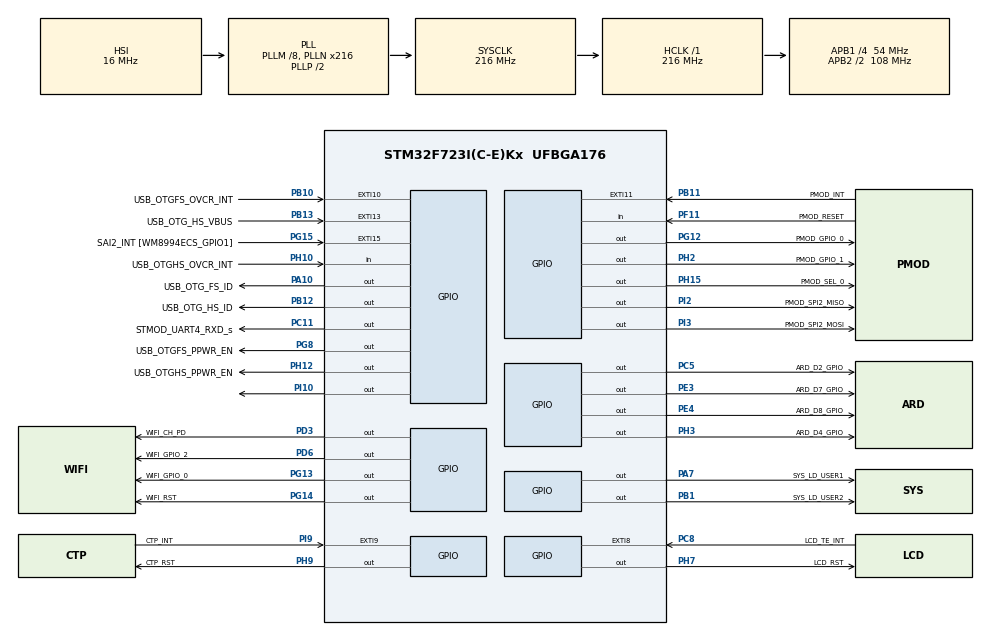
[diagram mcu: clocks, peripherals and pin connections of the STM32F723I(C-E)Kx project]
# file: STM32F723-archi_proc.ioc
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CORTEX_M7.AccessPermission-Cortex_Memory_Protection_Unit_Region0_Settings=MPU_REGION_FULL_ACCESS
CORTEX_M7.BaseAddress-Cortex_Memory_Protection_Unit_Region0_Settings=0x64000000
CORTEX_M7.CPU_DCache=Enabled
CORTEX_M7.CPU_ICache=Enabled
CORTEX_M7.Enable-Cortex_Memory_Protection_Unit_Region0_Settings=MPU_REGION_ENABLE
CORTEX_M7.IsBufferable-Cortex_Memory_Protection_Unit_Region0_Settings=MPU_ACCESS_BUFFERABLE
CORTEX_M7.IsCacheable-Cortex_Memory_Protection_Unit_Region0_Settings=MPU_ACCESS_CACHEABLE
CORTEX_M7.IsShareable-Cortex_Memory_Protection_Unit_Region0_Settings=MPU_ACCESS_SHAREABLE
CORTEX_M7.MPU_Control=MPU_PRIVILEGED_DEFAULT
CORTEX_M7.PREFETCH_ENABLE=0
CORTEX_M7.Size-Cortex_Memory_Protection_Unit_Region0_Settings=MPU_REGION_SIZE_1MB
Mcu.Family=STM32F7
Mcu.Name=STM32F723I(C-E)Kx
Mcu.Package=UFBGA176
NVIC.PriorityGroup=NVIC_PRIORITYGROUP_4
PA0-WKUP.GPIO_Label=SYS_B_User
PA0-WKUP.Signal=SYS_WKUP1
PA1.GPIO_Label=ARD_D10_TIM2_CH2_SPI1_NSS
PA1.Signal=S_TIM2_CH2
PA10.GPIO_Label=USB_OTG_FS_ID
PA10.Signal=GPIO_Output
PA11.Signal=USB_OTG_FS_DM
PA12.Signal=USB_OTG_FS_DP
PA13.Signal=SYS_JTMS-SWDIO
PA14.Signal=SYS_JTCK-SWCLK
PA15.GPIO_Label=STMOD_TIM2_CH1_2_ETR
PA15.Signal=S_TIM2_CH1_ETR
PA2.GPIO_Label=ARD_D1_USART2_TX
PA2.Signal=USART2_TX
PA3.GPIO_Label=ARD_D0_USART2_RX
PA3.Signal=USART2_RX
PA4.GPIO_Label=ARD_A1
PA4.Signal=ADCx_IN4
PA5.GPIO_Label=ARD_D13_SPI1_SCK
PA5.Signal=SPI1_SCK
PA6.GPIO_Label=ARD_A0
PA6.Signal=ADCx_IN6
PA7.GPIO_Label=SYS_LD_USER1
PA7.Signal=GPIO_Output
PA8.GPIO_Label=CTP_SCL
PA8.Signal=I2C3_SCL
PA9.Signal=USB_OTG_FS_VBUS
PB0.GPIO_Label=ARD_D5_STMOD_TIM3_CH3
PB0.Signal=S_TIM3_CH3
PB1.GPIO_Label=SYS_LD_USER2
PB1.Signal=GPIO_Output
PB10.GPIO_Label=USB_OTGFS_OVCR_INT
PB10.Signal=GPXTI10
PB11.GPIO_Label=PMOD_INT
PB11.Signal=GPXTI11
PB12.GPIO_Label=USB_OTG_HS_ID
PB12.Signal=GPIO_Output
PB13.GPIO_Label=USB_OTG_HS_VBUS
PB13.Signal=GPXTI13
PB14.Signal=USB_OTG_HS_DM
PB15.Signal=USB_OTG_HS_DP
PB2.GPIO_Label=QSPI_CLK [MX25L51245G_SCLK]
PB2.Signal=QUADSPI_CLK
PB3.GPIO_Label=SYS_STLINK_JTDO_SWO
PB3.Signal=SYS_JTDO-SWO
PB4.GPIO_Label=ARD_D12_SPI1_MISO
PB4.Signal=SPI1_MISO
PB5.GPIO_Label=ARD_D11_TIM3_CH2_SPI1_MOSI
PB5.Signal=SPI1_MOSI
PB6.GPIO_Label=QSPI_NCS [MX25L51245G_CS]
PB6.Signal=QUADSPI_BK1_NCS
PB7.GPIO_Label=NC1
PB7.Signal=FMC_NL
PB8.GPIO_Label=SAI2_I2C1_SCL [WM8994ECS/R_SCLK]
PB8.Signal=I2C1_SCL
PB9.GPIO_Label=SAI2_I2C1_SDA [WM8994ECS_SDA]
PB9.Signal=I2C1_SDA
PC0.GPIO_Label=ARD_A4
PC0.Signal=ADCx_IN10
PC1.GPIO_Label=ARD_A5
PC1.Signal=ADCx_IN11
PC10.GPIO_Label=QSPI_D1 [MX25L51245G_SIO1]
PC10.Signal=QUADSPI_BK1_IO1
PC11.GPIO_Label=STMOD_UART4_RXD_s
PC11.Signal=GPIO_Output
PC12.GPIO_Label=UART_TXD_WIFI_RX
PC12.Signal=UART5_TX
PC14-OSC32_IN.Signal=RCC_OSC32_IN
PC15-OSC32_OUT.Signal=RCC_OSC32_OUT
PC2.GPIO_Label=STMOD_SPI2_MISOs
PC2.Signal=SPI2_MISO
PC3.GPIO_Label=STMOD_SPI2_MOSIs
PC3.Signal=SPI2_MOSI
PC4.GPIO_Label=ARD_A2
PC4.Signal=ADCx_IN14
PC5.GPIO_Label=ARD_D2_GPIO
PC5.Signal=GPIO_Output
PC6.GPIO_Label=VCP_TX [STM32F103CBT6_PA3]
PC6.Signal=USART6_TX
PC7.GPIO_Label=VCP_RX [STM32F103CBT6_PA2]
PC7.Signal=USART6_RX
PC8.GPIO_Label=LCD_TE_INT
PC8.Signal=GPXTI8
PC9.GPIO_Label=QSPI_D0 [MX25L51245G_SIO0]
PC9.Signal=QUADSPI_BK1_IO0
PD0.GPIO_Label=LCD_PSRAM_D2
PD0.Signal=FMC_D2_DA2
PD1.GPIO_Label=LCD_PSRAM_D3
PD1.Signal=FMC_D3_DA3
PD10.GPIO_Label=LCD_PSRAM_D15
PD10.Signal=FMC_D15_DA15
PD11.GPIO_Label=PSRAM_A16
PD11.Signal=FMC_A16_CLE
PD12.GPIO_Label=PSRAM_A17
PD12.Signal=FMC_A17_ALE
PD13.GPIO_Label=QSPI_D3 [MX25L51245G_SIO3]
PD13.Signal=QUADSPI_BK1_IO3
PD14.GPIO_Label=LCD_PSRAM_D0
PD14.Signal=FMC_D0_DA0
PD15.GPIO_Label=LCD_PSRAM_D1
PD15.Signal=FMC_D1_DA1
PD2.GPIO_Label=UART_RXD_WIFI_TX
PD2.Signal=UART5_RX
PD3.GPIO_Label=WIFI_CH_PD
PD3.Signal=GPIO_Output
PD4.GPIO_Label=LCD_PSRAM_NWE
PD4.Signal=FMC_NOE
PD5.GPIO_Label=LCD_PSRAM_NWE
PD5.Signal=FMC_NWE
PD6.GPIO_Label=WIFI_GPIO_2
PD6.Signal=GPIO_Output
PD7.GPIO_Label=PSRAM_NE1 [IS66WV51216EBLL_CS1]
PD7.Signal=FMC_NE1
PD8.GPIO_Label=LCD_PSRAM_D13
PD8.Signal=FMC_D13_DA13
PD9.GPIO_Label=LCD_PSRAM_D14
PD9.Signal=FMC_D14_DA14
PE0.GPIO_Label=PSRAM_NBL0 [IS66WV51216EBLL_LB]
PE0.Signal=FMC_NBL0
PE1.GPIO_Label=PSRAM_NBL1 [IS66WV51216EBLL_UB]
PE1.Signal=FMC_NBL1
PE10.GPIO_Label=LCD_PSRAM_D7
PE10.Signal=FMC_D7_DA7
PE11.GPIO_Label=LCD_PSRAM_D8
PE11.Signal=FMC_D8_DA8
PE12.GPIO_Label=LCD_PSRAM_D9
PE12.Signal=FMC_D9_DA9
PE13.GPIO_Label=LCD_PSRAM_D10
PE13.Signal=FMC_D10_DA10
PE14.GPIO_Label=LCD_PSRAM_D11
PE14.Signal=FMC_D11_DA11
PE15.GPIO_Label=LCD_PSRAM_D12
PE15.Signal=FMC_D12_DA12
PE2.GPIO_Label=QSPI_D2 [MX25L51245G_SIO2]
PE2.Signal=QUADSPI_BK1_IO2
PE3.GPIO_Label=ARD_D7_GPIO
PE3.Signal=GPIO_Output
PE4.GPIO_Label=ARD_D8_GPIO
PE4.Signal=GPIO_Output
PE5.GPIO_Label=ARD_D3_TIM9_CH1
PE5.Signal=S_TIM9_CH1
PE6.GPIO_Label=ARD_D6_TIM9_CH2
PE6.Signal=S_TIM9_CH2
PE7.GPIO_Label=LCD_PSRAM_D4
PE7.Signal=FMC_D4_DA4
PE8.GPIO_Label=LCD_PSRAM_D5
PE8.Signal=FMC_D5_DA5
PE9.GPIO_Label=LCD_PSRAM_D6
PE9.Signal=FMC_D6_DA6
PF0.GPIO_Label=PSRAM_A0
PF0.Signal=FMC_A0
PF1.GPIO_Label=PSRAM_A1
PF1.Signal=FMC_A1
PF10.GPIO_Label=ARD_A3_ADC3_IN8
PF10.Signal=ADC3_IN8
PF11.GPIO_Label=PMOD_RESET
PF11.Signal=GPIO_Input
PF12.GPIO_Label=PSRAM_A6
PF12.Signal=FMC_A6
PF13.GPIO_Label=PSRAM_A7
PF13.Signal=FMC_A7
PF14.GPIO_Label=PSRAM_A8
PF14.Signal=FMC_A8
PF15.GPIO_Label=PSRAM_A9
PF15.Signal=FMC_A9
PF2.GPIO_Label=PSRAM_A2
PF2.Signal=FMC_A2
PF3.GPIO_Label=PSRAM_A3
PF3.Signal=FMC_A3
PF4.GPIO_Label=PSRAM_A4
PF4.Signal=FMC_A4
PF5.GPIO_Label=PSRAM_A5
PF5.Signal=FMC_A5
PF6.GPIO_Label=PMOD_UART7_RXD
PF6.Signal=UART7_RX
PF7.GPIO_Label=PMOD_UART7_TXD
PF7.Signal=UART7_TX
PF8.GPIO_Label=PMOD_UART7_RTS
PF8.Signal=UART7_RTS
PF9.GPIO_Label=PMOD_UART7_CTS
PF9.Signal=UART7_CTS
PG0.GPIO_Label=PSRAM_A10
PG0.Signal=FMC_A10
PG1.GPIO_Label=PSRAM_A11
PG1.Signal=FMC_A11
PG10.GPIO_Label=SAI2_SD_B [SAI2_SD_B_ADCDAT1]
PG10.Signal=SAI2_SD_B
PG12.GPIO_Label=PMOD_GPIO_0
PG12.Signal=GPIO_Output
PG13.GPIO_Label=WIFI_GPIO_0
PG13.Signal=GPIO_Output
PG14.GPIO_Label=WIFI_RST
PG14.Signal=GPIO_Output
PG15.GPIO_Label=SAI2_INT [WM8994ECS_GPIO1]
PG15.Signal=GPXTI15
PG2.GPIO_Label=PSRAM_A12
PG2.Signal=FMC_A12
PG3.GPIO_Label=PSRAM_A13
PG3.Signal=FMC_A13
PG4.GPIO_Label=PSRAM_A14
PG4.Signal=FMC_A14_BA0
PG5.GPIO_Label=PSRAM_A15
PG5.Signal=FMC_A15_BA1
PG8.GPIO_Label=USB_OTGFS_PPWR_EN
PG8.Signal=GPIO_Output
PG9.GPIO_Label=LCD_NE
PG9.Signal=FMC_NE2
PH0-OSC_IN.Signal=RCC_OSC_IN
PH1-OSC_OUT.Signal=RCC_OSC_OUT
PH10.GPIO_Label=USB_OTGHS_OVCR_INT
PH10.Signal=GPIO_Input
PH11.GPIO_Label=LCD_BL [STLD40DPUR_EN]
PH11.Signal=S_TIM5_CH2
PH12.GPIO_Label=USB_OTGHS_PPWR_EN
PH12.Signal=GPIO_Output
PH13.GPIO_Label=STMOD_UART4_TXD
PH13.Signal=UART4_TX
PH14.GPIO_Label=STMOD_UART4_RXD
PH14.Signal=UART4_RX
PH15.GPIO_Label=PMOD_SEL_0
PH15.PinState=GPIO_PIN_SET
PH15.Signal=GPIO_Output
PH2.GPIO_Label=PMOD_GPIO_1
PH2.Signal=GPIO_Output
PH3.GPIO_Label=ARD_D4_GPIO
PH3.Signal=GPIO_Output
PH4.GPIO_Label=ARD_D15_STMOD_I2C2_SCL
PH4.Signal=I2C2_SCL
PH5.GPIO_Label=ARD_D14_STMOD_I2C2_SDA
PH5.Signal=I2C2_SDA
PH6.GPIO_Label=ARD_D9_TIM12_CH1
PH6.Signal=S_TIM12_CH1
PH7.GPIO_Label=LCD_RST
PH7.Signal=GPIO_Output
PH8.GPIO_Label=CTP_SDA
PH8.Signal=I2C3_SDA
PH9.GPIO_Label=CTP_RST
PH9.Signal=GPIO_Output
PI0.GPIO_Label=PMOD_SPI2_NSS
PI0.Signal=SPI2_NSS
PI1.GPIO_Label=PMOD_SPI2_SCK
PI1.Signal=SPI2_SCK
PI10.Signal=GPIO_Output
PI2.GPIO_Label=PMOD_SPI2_MISO
PI2.Signal=GPIO_Output
PI3.GPIO_Label=PMOD_SPI2_MOSI
PI3.Signal=GPIO_Output
PI4.GPIO_Label=SAI2_MCLK_A [WM8994ECS_MCLK1]
PI4.Signal=SAI2_MCLK_A
PI5.GPIO_Label=SAI2_SCK_A [WM8994ECS_BCLK1]
PI5.Signal=SAI2_SCK_A
PI6.GPIO_Label=SAI2_SD_A [WM8994ECS_DACDAT1]
PI6.Signal=SAI2_SD_A
PI7.GPIO_Label=SAI2_FS_A [WM8994ECS_LRCLK1]
PI7.Signal=SAI2_FS_A
PI9.GPIO_Label=CTP_INT
PI9.Signal=GPXTI9
ProjectManager.HeapSize=0x200
ProjectManager.StackSize=0x400
ProjectManager.TargetToolchain=STM32CubeIDE
RCC.AHBFreq_Value=216000000
RCC.APB1CLKDivider=RCC_HCLK_DIV4
RCC.APB1Freq_Value=54000000
RCC.APB1TimFreq_Value=108000000
RCC.APB2CLKDivider=RCC_HCLK_DIV2
RCC.APB2Freq_Value=108000000
RCC.APB2TimFreq_Value=216000000
RCC.CortexFreq_Value=216000000
RCC.HCLKFreq_Value=216000000
RCC.HSE_VALUE=25000000
RCC.HSI_VALUE=16000000
RCC.LSE_VALUE=32768
RCC.PLLM=8
RCC.PLLN=216
RCC.PLLQ=9
RCC.SYSCLKFreq_VALUE=216000000
RCC.SYSCLKSource=RCC_SYSCLKSOURCE_PLLCLK
RCC.USBFreq_Value=48000000
RCC.VCOOutputFreq_Value=432000000
SH.ADCx_IN10.0=ADC2_IN10
SH.ADCx_IN11.0=ADC2_IN11
SH.ADCx_IN14.0=ADC2_IN14
SH.ADCx_IN4.0=ADC2_IN4
SH.ADCx_IN6.0=ADC2_IN6
SH.FMC_A0.0=FMC_A0
SH.FMC_A1.0=FMC_A1
SH.FMC_A10.0=FMC_A10
SH.FMC_A11.0=FMC_A11
SH.FMC_A12.0=FMC_A12
SH.FMC_A13.0=FMC_A13
SH.FMC_A14_BA0.0=FMC_A14
SH.FMC_A15_BA1.0=FMC_A15
SH.FMC_A16_CLE.0=FMC_A16
SH.FMC_A17_ALE.0=FMC_A17
SH.FMC_A2.0=FMC_A2
SH.FMC_A3.0=FMC_A3
SH.FMC_A4.0=FMC_A4
SH.FMC_A5.0=FMC_A5
SH.FMC_A6.0=FMC_A6
SH.FMC_A7.0=FMC_A7
SH.FMC_A8.0=FMC_A8
SH.FMC_A9.0=FMC_A9
SH.FMC_D0_DA0.0=FMC_D0
SH.FMC_D10_DA10.0=FMC_D10
SH.FMC_D11_DA11.0=FMC_D11
SH.FMC_D12_DA12.0=FMC_D12
SH.FMC_D13_DA13.0=FMC_D13
SH.FMC_D14_DA14.0=FMC_D14
SH.FMC_D15_DA15.0=FMC_D15
SH.FMC_D1_DA1.0=FMC_D1
SH.FMC_D2_DA2.0=FMC_D2
SH.FMC_D3_DA3.0=FMC_D3
SH.FMC_D4_DA4.0=FMC_D4
SH.FMC_D5_DA5.0=FMC_D5
SH.FMC_D6_DA6.0=FMC_D6
SH.FMC_D7_DA7.0=FMC_D7
SH.FMC_D8_DA8.0=FMC_D8
SH.FMC_D9_DA9.0=FMC_D9
SH.FMC_NBL0.0=FMC_NBL0
SH.FMC_NBL1.0=FMC_NBL1
SH.FMC_NL.0=FMC_NL
SH.FMC_NOE.0=FMC_NOE
SH.FMC_NWE.0=FMC_NWE
SH.S_TIM12_CH1.0=TIM12_CH1
SH.S_TIM2_CH1_ETR.0=TIM2_CH1
SH.S_TIM2_CH2.0=TIM2_CH2
SH.S_TIM3_CH3.0=TIM3_CH3
SH.S_TIM5_CH2.0=TIM5_CH2
SH.S_TIM9_CH1.0=TIM9_CH1
SH.S_TIM9_CH2.0=TIM9_CH2
board=STM32F723E-DISCO

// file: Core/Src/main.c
/* USER CODE BEGIN Header */
/**
  ******************************************************************************
  * @file           : main.c
  * @brief          : Main program body
  ******************************************************************************
  * @attention
  *
  * Copyright (c) 2022 STMicroelectronics.
  * All rights reserved.
  *
  * This software is licensed under terms that can be found in the LICENSE file
  * in the root directory of this software component.
  * If no LICENSE file comes with this software, it is provided AS-IS.
  *
  ******************************************************************************
  */
/* USER CODE END Header */
#include "main.h"

/* USER CODE BEGIN Includes */
#include "myApp.h"
/* USER CODE END Includes */

void SystemClock_Config(void);
static void MPU_Config(void);
static void MX_GPIO_Init(void);

int main(void)
{

  /* MPU Configuration--------------------------------------------------------*/
  MPU_Config();

  /* Enable I-Cache---------------------------------------------------------*/
  SCB_EnableICache();

  /* Enable D-Cache---------------------------------------------------------*/
  SCB_EnableDCache();

  /* MCU Configuration--------------------------------------------------------*/

  /* Reset of all peripherals, Initializes the Flash interface and the Systick. */
  HAL_Init();

  /* Configure the system clock */
  SystemClock_Config();

  /* Initialize all configured peripherals */
  MX_GPIO_Init();
  /* USER CODE BEGIN 2 */
  myHelloWorld();
  /* USER CODE END 2 */
  mySort();
  /* Infinite loop */
  /* USER CODE BEGIN WHILE */
//  while (1)
//  {
//    /* USER CODE END WHILE */
//
//    /* USER CODE BEGIN 3 */
//  }
//  /* USER CODE END 3 */
}

void SystemClock_Config(void)
{
  RCC_OscInitTypeDef RCC_OscInitStruct = {0};
  RCC_ClkInitTypeDef RCC_ClkInitStruct = {0};

  /** Configure the main internal regulator output voltage
  */
  __HAL_RCC_PWR_CLK_ENABLE();
  __HAL_PWR_VOLTAGESCALING_CONFIG(PWR_REGULATOR_VOLTAGE_SCALE1);

  /** Initializes the RCC Oscillators according to the specified parameters
  * in the RCC_OscInitTypeDef structure.
  */
  RCC_OscInitStruct.OscillatorType = RCC_OSCILLATORTYPE_HSI;
  RCC_OscInitStruct.HSIState = RCC_HSI_ON;
  RCC_OscInitStruct.HSICalibrationValue = RCC_HSICALIBRATION_DEFAULT;
  RCC_OscInitStruct.PLL.PLLState = RCC_PLL_ON;
  RCC_OscInitStruct.PLL.PLLSource = RCC_PLLSOURCE_HSI;
  RCC_OscInitStruct.PLL.PLLM = 8;
  RCC_OscInitStruct.PLL.PLLN = 216;
  RCC_OscInitStruct.PLL.PLLP = RCC_PLLP_DIV2;
  RCC_OscInitStruct.PLL.PLLQ = 9;
  if (HAL_RCC_OscConfig(&RCC_OscInitStruct) != HAL_OK)
  {
    Error_Handler();
  }

  /** Activate the Over-Drive mode
  */
  if (HAL_PWREx_EnableOverDrive() != HAL_OK)
  {
    Error_Handler();
  }

  /** Initializes the CPU, AHB and APB buses clocks
  */
  RCC_ClkInitStruct.ClockType = RCC_CLOCKTYPE_HCLK|RCC_CLOCKTYPE_SYSCLK
                              |RCC_CLOCKTYPE_PCLK1|RCC_CLOCKTYPE_PCLK2;
  RCC_ClkInitStruct.SYSCLKSource = RCC_SYSCLKSOURCE_PLLCLK;
  RCC_ClkInitStruct.AHBCLKDivider = RCC_SYSCLK_DIV1;
  RCC_ClkInitStruct.APB1CLKDivider = RCC_HCLK_DIV4;
  RCC_ClkInitStruct.APB2CLKDivider = RCC_HCLK_DIV2;

  if (HAL_RCC_ClockConfig(&RCC_ClkInitStruct, FLASH_LATENCY_7) != HAL_OK)
  {
    Error_Handler();
  }
}

static void MX_GPIO_Init(void)
{
  GPIO_InitTypeDef GPIO_InitStruct = {0};

  /* GPIO Ports Clock Enable */
  __HAL_RCC_GPIOE_CLK_ENABLE();
  __HAL_RCC_GPIOB_CLK_ENABLE();
  __HAL_RCC_GPIOG_CLK_ENABLE();
  __HAL_RCC_GPIOD_CLK_ENABLE();
  __HAL_RCC_GPIOC_CLK_ENABLE();
  __HAL_RCC_GPIOA_CLK_ENABLE();
  __HAL_RCC_GPIOI_CLK_ENABLE();
  __HAL_RCC_GPIOH_CLK_ENABLE();
  __HAL_RCC_GPIOF_CLK_ENABLE();

  /*Configure GPIO pin Output Level */
  HAL_GPIO_WritePin(GPIOE, ARD_D7_GPIO_Pin|ARD_D8_GPIO_Pin, GPIO_PIN_RESET);

  /*Configure GPIO pin Output Level */
  HAL_GPIO_WritePin(GPIOG, WIFI_RST_Pin|WIFI_GPIO_0_Pin|PMOD_GPIO_0_Pin|USB_OTGFS_PPWR_EN_Pin, GPIO_PIN_RESET);

  /*Configure GPIO pin Output Level */
  HAL_GPIO_WritePin(GPIOD, WIFI_GPIO_2_Pin|WIFI_CH_PD_Pin, GPIO_PIN_RESET);

  /*Configure GPIO pin Output Level */
  HAL_GPIO_WritePin(GPIOC, STMOD_UART4_RXD_s_Pin|ARD_D2_GPIO_Pin, GPIO_PIN_RESET);

  /*Configure GPIO pin Output Level */
  HAL_GPIO_WritePin(GPIOI, PMOD_SPI2_MOSI_Pin|PMOD_SPI2_MISO_Pin|GPIO_PIN_10, GPIO_PIN_RESET);

  /*Configure GPIO pin Output Level */
  HAL_GPIO_WritePin(PMOD_SEL_0_GPIO_Port, PMOD_SEL_0_Pin, GPIO_PIN_SET);

  /*Configure GPIO pin Output Level */
  HAL_GPIO_WritePin(GPIOA, USB_OTG_FS_ID_Pin|SYS_LD_USER1_Pin, GPIO_PIN_RESET);

  /*Configure GPIO pin Output Level */
  HAL_GPIO_WritePin(GPIOH, PMOD_GPIO_1_Pin|ARD_D4_GPIO_Pin|USB_OTGHS_PPWR_EN_Pin|CTP_RST_Pin
                          |LCD_RST_Pin, GPIO_PIN_RESET);

  /*Configure GPIO pin Output Level */
  HAL_GPIO_WritePin(GPIOB, USB_OTG_HS_ID_Pin|SYS_LD_USER2_Pin, GPIO_PIN_RESET);

  /*Configure GPIO pins : ARD_D7_GPIO_Pin ARD_D8_GPIO_Pin */
  GPIO_InitStruct.Pin = ARD_D7_GPIO_Pin|ARD_D8_GPIO_Pin;
  GPIO_InitStruct.Mode = GPIO_MODE_OUTPUT_PP;
  GPIO_InitStruct.Pull = GPIO_NOPULL;
  GPIO_InitStruct.Speed = GPIO_SPEED_FREQ_LOW;
  HAL_GPIO_Init(GPIOE, &GPIO_InitStruct);

  /*Configure GPIO pin : QSPI_D2_Pin */
  GPIO_InitStruct.Pin = QSPI_D2_Pin;
  GPIO_InitStruct.Mode = GPIO_MODE_AF_PP;
  GPIO_InitStruct.Pull = GPIO_NOPULL;
  GPIO_InitStruct.Speed = GPIO_SPEED_FREQ_VERY_HIGH;
  GPIO_InitStruct.Alternate = GPIO_AF9_QUADSPI;
  HAL_GPIO_Init(QSPI_D2_GPIO_Port, &GPIO_InitStruct);

  /*Configure GPIO pins : PSRAM_NBL1_Pin PSRAM_NBL0_Pin LCD_PSRAM_D10_Pin LCD_PSRAM_D5_Pin
                           LCD_PSRAM_D6_Pin LCD_PSRAM_D8_Pin LCD_PSRAM_D11_Pin LCD_PSRAM_D4_Pin
                           LCD_PSRAM_D7_Pin LCD_PSRAM_D9_Pin LCD_PSRAM_D12_Pin */
  GPIO_InitStruct.Pin = PSRAM_NBL1_Pin|PSRAM_NBL0_Pin|LCD_PSRAM_D10_Pin|LCD_PSRAM_D5_Pin
                          |LCD_PSRAM_D6_Pin|LCD_PSRAM_D8_Pin|LCD_PSRAM_D11_Pin|LCD_PSRAM_D4_Pin
                          |LCD_PSRAM_D7_Pin|LCD_PSRAM_D9_Pin|LCD_PSRAM_D12_Pin;
  GPIO_InitStruct.Mode = GPIO_MODE_AF_PP;
  GPIO_InitStruct.Pull = GPIO_NOPULL;
  GPIO_InitStruct.Speed = GPIO_SPEED_FREQ_VERY_HIGH;
  GPIO_InitStruct.Alternate = GPIO_AF12_FMC;
  HAL_GPIO_Init(GPIOE, &GPIO_InitStruct);

  /*Configure GPIO pins : SAI2_I2C1_SCL_Pin SAI2_I2C1_SDA_Pin */
  GPIO_InitStruct.Pin = SAI2_I2C1_SCL_Pin|SAI2_I2C1_SDA_Pin;
  GPIO_InitStruct.Mode = GPIO_MODE_AF_OD;
  GPIO_InitStruct.Pull = GPIO_NOPULL;
  GPIO_InitStruct.Speed = GPIO_SPEED_FREQ_VERY_HIGH;
  GPIO_InitStruct.Alternate = GPIO_AF4_I2C1;
  HAL_GPIO_Init(GPIOB, &GPIO_InitStruct);

  /*Configure GPIO pins : ARD_D11_TIM3_CH2_SPI1_MOSI_Pin ARD_D12_SPI1_MISO_Pin */
  GPIO_InitStruct.Pin = ARD_D11_TIM3_CH2_SPI1_MOSI_Pin|ARD_D12_SPI1_MISO_Pin;
  GPIO_InitStruct.Mode = GPIO_MODE_AF_PP;
  GPIO_InitStruct.Pull = GPIO_NOPULL;
  GPIO_InitStruct.Speed = GPIO_SPEED_FREQ_VERY_HIGH;
  GPIO_InitStruct.Alternate = GPIO_AF5_SPI1;
  HAL_GPIO_Init(GPIOB, &GPIO_InitStruct);

  /*Configure GPIO pins : WIFI_RST_Pin WIFI_GPIO_0_Pin PMOD_GPIO_0_Pin USB_OTGFS_PPWR_EN_Pin */
  GPIO_InitStruct.Pin = WIFI_RST_Pin|WIFI_GPIO_0_Pin|PMOD_GPIO_0_Pin|USB_OTGFS_PPWR_EN_Pin;
  GPIO_InitStruct.Mode = GPIO_MODE_OUTPUT_PP;
  GPIO_InitStruct.Pull = GPIO_NOPULL;
  GPIO_InitStruct.Speed = GPIO_SPEED_FREQ_LOW;
  HAL_GPIO_Init(GPIOG, &GPIO_InitStruct);

  /*Configure GPIO pins : PSRAM_NE1_Pin LCD_PSRAM_D2_Pin LCD_PSRAM_NWE_Pin LCD_PSRAM_D3_Pin
                           LCD_PSRAM_NWED4_Pin LCD_PSRAM_D1_Pin LCD_PSRAM_D0_Pin PSRAM_A17_Pin
                           PSRAM_A16_Pin LCD_PSRAM_D15_Pin LCD_PSRAM_D14_Pin LCD_PSRAM_D13_Pin */
  GPIO_InitStruct.Pin = PSRAM_NE1_Pin|LCD_PSRAM_D2_Pin|LCD_PSRAM_NWE_Pin|LCD_PSRAM_D3_Pin
                          |LCD_PSRAM_NWED4_Pin|LCD_PSRAM_D1_Pin|LCD_PSRAM_D0_Pin|PSRAM_A17_Pin
                          |PSRAM_A16_Pin|LCD_PSRAM_D15_Pin|LCD_PSRAM_D14_Pin|LCD_PSRAM_D13_Pin;
  GPIO_InitStruct.Mode = GPIO_MODE_AF_PP;
  GPIO_InitStruct.Pull = GPIO_NOPULL;
  GPIO_InitStruct.Speed = GPIO_SPEED_FREQ_VERY_HIGH;
  GPIO_InitStruct.Alternate = GPIO_AF12_FMC;
  HAL_GPIO_Init(GPIOD, &GPIO_InitStruct);

  /*Configure GPIO pin : UART_TXD_WIFI_RX_Pin */
  GPIO_InitStruct.Pin = UART_TXD_WIFI_RX_Pin;
  GPIO_InitStruct.Mode = GPIO_MODE_AF_PP;
  GPIO_InitStruct.Pull = GPIO_NOPULL;
  GPIO_InitStruct.Speed = GPIO_SPEED_FREQ_VERY_HIGH;
  GPIO_InitStruct.Alternate = GPIO_AF8_UART5;
  HAL_GPIO_Init(UART_TXD_WIFI_RX_GPIO_Port, &GPIO_InitStruct);

  /*Configure GPIO pins : STMOD_TIM2_CH1_2_ETR_Pin ARD_D10_TIM2_CH2_SPI1_NSS_Pin */
  GPIO_InitStruct.Pin = STMOD_TIM2_CH1_2_ETR_Pin|ARD_D10_TIM2_CH2_SPI1_NSS_Pin;
  GPIO_InitStruct.Mode = GPIO_MODE_AF_PP;
  GPIO_InitStruct.Pull = GPIO_NOPULL;
  GPIO_InitStruct.Speed = GPIO_SPEED_FREQ_LOW;
  GPIO_InitStruct.Alternate = GPIO_AF1_TIM2;
  HAL_GPIO_Init(GPIOA, &GPIO_InitStruct);

  /*Configure GPIO pins : ARD_D3_TIM9_CH1_Pin ARD_D6_TIM9_CH2_Pin */
  GPIO_InitStruct.Pin = ARD_D3_TIM9_CH1_Pin|ARD_D6_TIM9_CH2_Pin;
  GPIO_InitStruct.Mode = GPIO_MODE_AF_PP;
  GPIO_InitStruct.Pull = GPIO_NOPULL;
  GPIO_InitStruct.Speed = GPIO_SPEED_FREQ_LOW;
  GPIO_InitStruct.Alternate = GPIO_AF3_TIM9;
  HAL_GPIO_Init(GPIOE, &GPIO_InitStruct);

  /*Configure GPIO pin : NC1_Pin */
  GPIO_InitStruct.Pin = NC1_Pin;
  GPIO_InitStruct.Mode = GPIO_MODE_AF_PP;
  GPIO_InitStruct.Pull = GPIO_NOPULL;
  GPIO_InitStruct.Speed = GPIO_SPEED_FREQ_VERY_HIGH;
  GPIO_InitStruct.Alternate = GPIO_AF12_FMC;
  HAL_GPIO_Init(NC1_GPIO_Port, &GPIO_InitStruct);

  /*Configure GPIO pin : QSPI_NCS_Pin */
  GPIO_InitStruct.Pin = QSPI_NCS_Pin;
  GPIO_InitStruct.Mode = GPIO_MODE_AF_PP;
  GPIO_InitStruct.Pull = GPIO_NOPULL;
  GPIO_InitStruct.Speed = GPIO_SPEED_FREQ_VERY_HIGH;
  GPIO_InitStruct.Alternate = GPIO_AF10_QUADSPI;
  HAL_GPIO_Init(QSPI_NCS_GPIO_Port, &GPIO_InitStruct);

  /*Configure GPIO pin : SAI2_INT_Pin */
  GPIO_InitStruct.Pin = SAI2_INT_Pin;
  GPIO_InitStruct.Mode = GPIO_MODE_IT_RISING;
  GPIO_InitStruct.Pull = GPIO_NOPULL;
  HAL_GPIO_Init(SAI2_INT_GPIO_Port, &GPIO_InitStruct);

  /*Configure GPIO pin : SAI2_SD_B_Pin */
  GPIO_InitStruct.Pin = SAI2_SD_B_Pin;
  GPIO_InitStruct.Mode = GPIO_MODE_AF_PP;
  GPIO_InitStruct.Pull = GPIO_NOPULL;
  GPIO_InitStruct.Speed = GPIO_SPEED_FREQ_LOW;
  GPIO_InitStruct.Alternate = GPIO_AF10_SAI2;
  HAL_GPIO_Init(SAI2_SD_B_GPIO_Port, &GPIO_InitStruct);

  /*Configure GPIO pins : WIFI_GPIO_2_Pin WIFI_CH_PD_Pin */
  GPIO_InitStruct.Pin = WIFI_GPIO_2_Pin|WIFI_CH_PD_Pin;
  GPIO_InitStruct.Mode = GPIO_MODE_OUTPUT_PP;
  GPIO_InitStruct.Pull = GPIO_NOPULL;
  GPIO_InitStruct.Speed = GPIO_SPEED_FREQ_LOW;
  HAL_GPIO_Init(GPIOD, &GPIO_InitStruct);

  /*Configure GPIO pins : STMOD_UART4_RXD_s_Pin ARD_D2_GPIO_Pin */
  GPIO_InitStruct.Pin = STMOD_UART4_RXD_s_Pin|ARD_D2_GPIO_Pin;
  GPIO_InitStruct.Mode = GPIO_MODE_OUTPUT_PP;
  GPIO_InitStruct.Pull = GPIO_NOPULL;
  GPIO_InitStruct.Speed = GPIO_SPEED_FREQ_LOW;
  HAL_GPIO_Init(GPIOC, &GPIO_InitStruct);

  /*Configure GPIO pins : QSPI_D1_Pin QSPI_D0_Pin */
  GPIO_InitStruct.Pin = QSPI_D1_Pin|QSPI_D0_Pin;
  GPIO_InitStruct.Mode = GPIO_MODE_AF_PP;
  GPIO_InitStruct.Pull = GPIO_NOPULL;
  GPIO_InitStruct.Speed = GPIO_SPEED_FREQ_VERY_HIGH;
  GPIO_InitStruct.Alternate = GPIO_AF9_QUADSPI;
  HAL_GPIO_Init(GPIOC, &GPIO_InitStruct);

  /*Configure GPIO pins : PA12 PA11 */
  GPIO_InitStruct.Pin = GPIO_PIN_12|GPIO_PIN_11;
  GPIO_InitStruct.Mode = GPIO_MODE_AF_PP;
  GPIO_InitStruct.Pull = GPIO_NOPULL;
  GPIO_InitStruct.Speed = GPIO_SPEED_FREQ_VERY_HIGH;
  GPIO_InitStruct.Alternate = GPIO_AF10_OTG_FS;
  HAL_GPIO_Init(GPIOA, &GPIO_InitStruct);

  /*Configure GPIO pins : SAI2_FS_A_Pin SAI2_SD_A_Pin SAI2_SCK_A_Pin SAI2_MCLK_A_Pin */
  GPIO_InitStruct.Pin = SAI2_FS_A_Pin|SAI2_SD_A_Pin|SAI2_SCK_A_Pin|SAI2_MCLK_A_Pin;
  GPIO_InitStruct.Mode = GPIO_MODE_AF_PP;
  GPIO_InitStruct.Pull = GPIO_NOPULL;
  GPIO_InitStruct.Speed = GPIO_SPEED_FREQ_LOW;
  GPIO_InitStruct.Alternate = GPIO_AF10_SAI2;
  HAL_GPIO_Init(GPIOI, &GPIO_InitStruct);

  /*Configure GPIO pins : LCD_NE_Pin PSRAM_A15_Pin PSRAM_A14_Pin PSRAM_A13_Pin
                           PSRAM_A12_Pin PSRAM_A11_Pin PSRAM_A10_Pin */
  GPIO_InitStruct.Pin = LCD_NE_Pin|PSRAM_A15_Pin|PSRAM_A14_Pin|PSRAM_A13_Pin
                          |PSRAM_A12_Pin|PSRAM_A11_Pin|PSRAM_A10_Pin;
  GPIO_InitStruct.Mode = GPIO_MODE_AF_PP;
  GPIO_InitStruct.Pull = GPIO_NOPULL;
  GPIO_InitStruct.Speed = GPIO_SPEED_FREQ_VERY_HIGH;
  GPIO_InitStruct.Alternate = GPIO_AF12_FMC;
  HAL_GPIO_Init(GPIOG, &GPIO_InitStruct);

  /*Configure GPIO pins : PMOD_SPI2_MOSI_Pin PMOD_SPI2_MISO_Pin PI10 */
  GPIO_InitStruct.Pin = PMOD_SPI2_MOSI_Pin|PMOD_SPI2_MISO_Pin|GPIO_PIN_10;
  GPIO_InitStruct.Mode = GPIO_MODE_OUTPUT_PP;
  GPIO_InitStruct.Pull = GPIO_NOPULL;
  GPIO_InitStruct.Speed = GPIO_SPEED_FREQ_LOW;
  HAL_GPIO_Init(GPIOI, &GPIO_InitStruct);

  /*Configure GPIO pin : CTP_INT_Pin */
  GPIO_InitStruct.Pin = CTP_INT_Pin;
  GPIO_InitStruct.Mode = GPIO_MODE_IT_RISING;
  GPIO_InitStruct.Pull = GPIO_NOPULL;
  HAL_GPIO_Init(CTP_INT_GPIO_Port, &GPIO_InitStruct);

  /*Configure GPIO pin : UART_RXD_WIFI_TX_Pin */
  GPIO_InitStruct.Pin = UART_RXD_WIFI_TX_Pin;
  GPIO_InitStruct.Mode = GPIO_MODE_AF_PP;
  GPIO_InitStruct.Pull = GPIO_NOPULL;
  GPIO_InitStruct.Speed = GPIO_SPEED_FREQ_VERY_HIGH;
  GPIO_InitStruct.Alternate = GPIO_AF8_UART5;
  HAL_GPIO_Init(UART_RXD_WIFI_TX_GPIO_Port, &GPIO_InitStruct);

  /*Configure GPIO pins : PMOD_SEL_0_Pin PMOD_GPIO_1_Pin ARD_D4_GPIO_Pin USB_OTGHS_PPWR_EN_Pin
                           CTP_RST_Pin LCD_RST_Pin */
  GPIO_InitStruct.Pin = PMOD_SEL_0_Pin|PMOD_GPIO_1_Pin|ARD_D4_GPIO_Pin|USB_OTGHS_PPWR_EN_Pin
                          |CTP_RST_Pin|LCD_RST_Pin;
  GPIO_InitStruct.Mode = GPIO_MODE_OUTPUT_PP;
  GPIO_InitStruct.Pull = GPIO_NOPULL;
  GPIO_InitStruct.Speed = GPIO_SPEED_FREQ_LOW;
  HAL_GPIO_Init(GPIOH, &GPIO_InitStruct);

  /*Configure GPIO pins : PMOD_SPI2_SCK_Pin PMOD_SPI2_NSS_Pin */
  GPIO_InitStruct.Pin = PMOD_SPI2_SCK_Pin|PMOD_SPI2_NSS_Pin;
  GPIO_InitStruct.Mode = GPIO_MODE_AF_PP;
  GPIO_InitStruct.Pull = GPIO_NOPULL;
  GPIO_InitStruct.Speed = GPIO_SPEED_FREQ_VERY_HIGH;
  GPIO_InitStruct.Alternate = GPIO_AF5_SPI2;
  HAL_GPIO_Init(GPIOI, &GPIO_InitStruct);

  /*Configure GPIO pins : USB_OTG_FS_ID_Pin SYS_LD_USER1_Pin */
  GPIO_InitStruct.Pin = USB_OTG_FS_ID_Pin|SYS_LD_USER1_Pin;
  GPIO_InitStruct.Mode = GPIO_MODE_OUTPUT_PP;
  GPIO_InitStruct.Pull = GPIO_NOPULL;
  GPIO_InitStruct.Speed = GPIO_SPEED_FREQ_LOW;
  HAL_GPIO_Init(GPIOA, &GPIO_InitStruct);

  /*Configure GPIO pins : PSRAM_A0_Pin PSRAM_A2_Pin PSRAM_A1_Pin PSRAM_A3_Pin
                           PSRAM_A4_Pin PSRAM_A5_Pin PSRAM_A7_Pin PSRAM_A6_Pin
                           PSRAM_A9_Pin PSRAM_A8_Pin */
  GPIO_InitStruct.Pin = PSRAM_A0_Pin|PSRAM_A2_Pin|PSRAM_A1_Pin|PSRAM_A3_Pin
                          |PSRAM_A4_Pin|PSRAM_A5_Pin|PSRAM_A7_Pin|PSRAM_A6_Pin
                          |PSRAM_A9_Pin|PSRAM_A8_Pin;
  GPIO_InitStruct.Mode = GPIO_MODE_AF_PP;
  GPIO_InitStruct.Pull = GPIO_NOPULL;
  GPIO_InitStruct.Speed = GPIO_SPEED_FREQ_VERY_HIGH;
  GPIO_InitStruct.Alternate = GPIO_AF12_FMC;
  HAL_GPIO_Init(GPIOF, &GPIO_InitStruct);

  /*Configure GPIO pins : STMOD_UART4_TXD_Pin STMOD_UART4_RXD_Pin */
  GPIO_InitStruct.Pin = STMOD_UART4_TXD_Pin|STMOD_UART4_RXD_Pin;
  GPIO_InitStruct.Mode = GPIO_MODE_AF_PP;
  GPIO_InitStruct.Pull = GPIO_NOPULL;
  GPIO_InitStruct.Speed = GPIO_SPEED_FREQ_VERY_HIGH;
  GPIO_InitStruct.Alternate = GPIO_AF8_UART4;
  HAL_GPIO_Init(GPIOH, &GPIO_InitStruct);

  /*Configure GPIO pin : PA9 */
  GPIO_InitStruct.Pin = GPIO_PIN_9;
  GPIO_InitStruct.Mode = GPIO_MODE_INPUT;
  GPIO_InitStruct.Pull = GPIO_NOPULL;
  HAL_GPIO_Init(GPIOA, &GPIO_InitStruct);

  /*Configure GPIO pin : CTP_SCL_Pin */
  GPIO_InitStruct.Pin = CTP_SCL_Pin;
  GPIO_InitStruct.Mode = GPIO_MODE_AF_OD;
  GPIO_InitStruct.Pull = GPIO_NOPULL;
  GPIO_InitStruct.Speed = GPIO_SPEED_FREQ_VERY_HIGH;
  GPIO_InitStruct.Alternate = GPIO_AF4_I2C3;
  HAL_GPIO_Init(CTP_SCL_GPIO_Port, &GPIO_InitStruct);

  /*Configure GPIO pin : LCD_TE_INT_Pin */
  GPIO_InitStruct.Pin = LCD_TE_INT_Pin;
  GPIO_InitStruct.Mode = GPIO_MODE_IT_RISING;
  GPIO_InitStruct.Pull = GPIO_NOPULL;
  HAL_GPIO_Init(LCD_TE_INT_GPIO_Port, &GPIO_InitStruct);

  /*Configure GPIO pins : VCP_RX_Pin VCP_TX_Pin */
  GPIO_InitStruct.Pin = VCP_RX_Pin|VCP_TX_Pin;
  GPIO_InitStruct.Mode = GPIO_MODE_AF_PP;
  GPIO_InitStruct.Pull = GPIO_NOPULL;
  GPIO_InitStruct.Speed = GPIO_SPEED_FREQ_VERY_HIGH;
  GPIO_InitStruct.Alternate = GPIO_AF8_USART6;
  HAL_GPIO_Init(GPIOC, &GPIO_InitStruct);

  /*Configure GPIO pins : ARD_D15_STMOD_I2C2_SCL_Pin ARD_D14_STMOD_I2C2_SDA_Pin */
  GPIO_InitStruct.Pin = ARD_D15_STMOD_I2C2_SCL_Pin|ARD_D14_STMOD_I2C2_SDA_Pin;
  GPIO_InitStruct.Mode = GPIO_MODE_AF_OD;
  GPIO_InitStruct.Pull = GPIO_NOPULL;
  GPIO_InitStruct.Speed = GPIO_SPEED_FREQ_VERY_HIGH;
  GPIO_InitStruct.Alternate = GPIO_AF4_I2C2;
  HAL_GPIO_Init(GPIOH, &GPIO_InitStruct);

  /*Configure GPIO pins : PMOD_UART7_TXD_Pin PMOD_UART7_RXD_Pin PMOD_UART7_CTS_Pin PMOD_UART7_RTS_Pin */
  GPIO_InitStruct.Pin = PMOD_UART7_TXD_Pin|PMOD_UART7_RXD_Pin|PMOD_UART7_CTS_Pin|PMOD_UART7_RTS_Pin;
  GPIO_InitStruct.Mode = GPIO_MODE_AF_PP;
  GPIO_InitStruct.Pull = GPIO_NOPULL;
  GPIO_InitStruct.Speed = GPIO_SPEED_FREQ_VERY_HIGH;
  GPIO_InitStruct.Alternate = GPIO_AF8_UART7;
  HAL_GPIO_Init(GPIOF, &GPIO_InitStruct);

  /*Configure GPIO pin : ARD_A3_ADC3_IN8_Pin */
  GPIO_InitStruct.Pin = ARD_A3_ADC3_IN8_Pin;
  GPIO_InitStruct.Mode = GPIO_MODE_ANALOG;
  GPIO_InitStruct.Pull = GPIO_NOPULL;
  HAL_GPIO_Init(ARD_A3_ADC3_IN8_GPIO_Port, &GPIO_InitStruct);

  /*Configure GPIO pin : LCD_BL_Pin */
  GPIO_InitStruct.Pin = LCD_BL_Pin;
  GPIO_InitStruct.Mode = GPIO_MODE_AF_PP;
  GPIO_InitStruct.Pull = GPIO_NOPULL;
  GPIO_InitStruct.Speed = GPIO_SPEED_FREQ_LOW;
  GPIO_InitStruct.Alternate = GPIO_AF2_TIM5;
  HAL_GPIO_Init(LCD_BL_GPIO_Port, &GPIO_InitStruct);

  /*Configure GPIO pin : USB_OTGHS_OVCR_INT_Pin */
  GPIO_InitStruct.Pin = USB_OTGHS_OVCR_INT_Pin;
  GPIO_InitStruct.Mode = GPIO_MODE_INPUT;
  GPIO_InitStruct.Pull = GPIO_NOPULL;
  HAL_GPIO_Init(USB_OTGHS_OVCR_INT_GPIO_Port, &GPIO_InitStruct);

  /*Configure GPIO pins : ARD_A4_Pin ARD_A5_Pin ARD_A2_Pin */
  GPIO_InitStruct.Pin = ARD_A4_Pin|ARD_A5_Pin|ARD_A2_Pin;
  GPIO_InitStruct.Mode = GPIO_MODE_ANALOG;
  GPIO_InitStruct.Pull = GPIO_NOPULL;
  HAL_GPIO_Init(GPIOC, &GPIO_InitStruct);

  /*Configure GPIO pins : STMOD_SPI2_MISOs_Pin STMOD_SPI2_MOSIs_Pin */
  GPIO_InitStruct.Pin = STMOD_SPI2_MISOs_Pin|STMOD_SPI2_MOSIs_Pin;
  GPIO_InitStruct.Mode = GPIO_MODE_AF_PP;
  GPIO_InitStruct.Pull = GPIO_NOPULL;
  GPIO_InitStruct.Speed = GPIO_SPEED_FREQ_VERY_HIGH;
  GPIO_InitStruct.Alternate = GPIO_AF5_SPI2;
  HAL_GPIO_Init(GPIOC, &GPIO_InitStruct);

  /*Configure GPIO pin : QSPI_CLK_Pin */
  GPIO_InitStruct.Pin = QSPI_CLK_Pin;
  GPIO_InitStruct.Mode = GPIO_MODE_AF_PP;
  GPIO_InitStruct.Pull = GPIO_NOPULL;
  GPIO_InitStruct.Speed = GPIO_SPEED_FREQ_VERY_HIGH;
  GPIO_InitStruct.Alternate = GPIO_AF9_QUADSPI;
  HAL_GPIO_Init(QSPI_CLK_GPIO_Port, &GPIO_InitStruct);

  /*Configure GPIO pin : ARD_D9_TIM12_CH1_Pin */
  GPIO_InitStruct.Pin = ARD_D9_TIM12_CH1_Pin;
  GPIO_InitStruct.Mode = GPIO_MODE_AF_PP;
  GPIO_InitStruct.Pull = GPIO_NOPULL;
  GPIO_InitStruct.Speed = GPIO_SPEED_FREQ_LOW;
  GPIO_InitStruct.Alternate = GPIO_AF9_TIM12;
  HAL_GPIO_Init(ARD_D9_TIM12_CH1_GPIO_Port, &GPIO_InitStruct);

  /*Configure GPIO pin : CTP_SDA_Pin */
  GPIO_InitStruct.Pin = CTP_SDA_Pin;
  GPIO_InitStruct.Mode = GPIO_MODE_AF_OD;
  GPIO_InitStruct.Pull = GPIO_NOPULL;
  GPIO_InitStruct.Speed = GPIO_SPEED_FREQ_VERY_HIGH;
  GPIO_InitStruct.Alternate = GPIO_AF4_I2C3;
  HAL_GPIO_Init(CTP_SDA_GPIO_Port, &GPIO_InitStruct);

  /*Configure GPIO pin : QSPI_D3_Pin */
  GPIO_InitStruct.Pin = QSPI_D3_Pin;
  GPIO_InitStruct.Mode = GPIO_MODE_AF_PP;
  GPIO_InitStruct.Pull = GPIO_NOPULL;
  GPIO_InitStruct.Speed = GPIO_SPEED_FREQ_VERY_HIGH;
  GPIO_InitStruct.Alternate = GPIO_AF9_QUADSPI;
  HAL_GPIO_Init(QSPI_D3_GPIO_Port, &GPIO_InitStruct);

  /*Configure GPIO pins : ARD_A1_Pin ARD_A0_Pin */
  GPIO_InitStruct.Pin = ARD_A1_Pin|ARD_A0_Pin;
  GPIO_InitStruct.Mode = GPIO_MODE_ANALOG;
  GPIO_InitStruct.Pull = GPIO_NOPULL;
  HAL_GPIO_Init(GPIOA, &GPIO_InitStruct);

  /*Configure GPIO pins : ARD_D1_USART2_TX_Pin ARD_D0_USART2_RX_Pin */
  GPIO_InitStruct.Pin = ARD_D1_USART2_TX_Pin|ARD_D0_USART2_RX_Pin;
  GPIO_InitStruct.Mode = GPIO_MODE_AF_PP;
  GPIO_InitStruct.Pull = GPIO_NOPULL;
  GPIO_InitStruct.Speed = GPIO_SPEED_FREQ_VERY_HIGH;
  GPIO_InitStruct.Alternate = GPIO_AF7_USART2;
  HAL_GPIO_Init(GPIOA, &GPIO_InitStruct);

  /*Configure GPIO pin : ARD_D13_SPI1_SCK_Pin */
  GPIO_InitStruct.Pin = ARD_D13_SPI1_SCK_Pin;
  GPIO_InitStruct.Mode = GPIO_MODE_AF_PP;
  GPIO_InitStruct.Pull = GPIO_NOPULL;
  GPIO_InitStruct.Speed = GPIO_SPEED_FREQ_VERY_HIGH;
  GPIO_InitStruct.Alternate = GPIO_AF5_SPI1;
  HAL_GPIO_Init(ARD_D13_SPI1_SCK_GPIO_Port, &GPIO_InitStruct);

  /*Configure GPIO pins : USB_OTG_HS_ID_Pin SYS_LD_USER2_Pin */
  GPIO_InitStruct.Pin = USB_OTG_HS_ID_Pin|SYS_LD_USER2_Pin;
  GPIO_InitStruct.Mode = GPIO_MODE_OUTPUT_PP;
  GPIO_InitStruct.Pull = GPIO_NOPULL;
  GPIO_InitStruct.Speed = GPIO_SPEED_FREQ_LOW;
  HAL_GPIO_Init(GPIOB, &GPIO_InitStruct);

  /*Configure GPIO pins : USB_OTG_HS_VBUS_Pin USB_OTGFS_OVCR_INT_Pin PMOD_INT_Pin */
  GPIO_InitStruct.Pin = USB_OTG_HS_VBUS_Pin|USB_OTGFS_OVCR_INT_Pin|PMOD_INT_Pin;
  GPIO_InitStruct.Mode = GPIO_MODE_IT_RISING;
  GPIO_InitStruct.Pull = GPIO_NOPULL;
  HAL_GPIO_Init(GPIOB, &GPIO_InitStruct);

  /*Configure GPIO pin : ARD_D5_STMOD_TIM3_CH3_Pin */
  GPIO_InitStruct.Pin = ARD_D5_STMOD_TIM3_CH3_Pin;
  GPIO_InitStruct.Mode = GPIO_MODE_AF_PP;
  GPIO_InitStruct.Pull = GPIO_NOPULL;
  GPIO_InitStruct.Speed = GPIO_SPEED_FREQ_LOW;
  GPIO_InitStruct.Alternate = GPIO_AF2_TIM3;
  HAL_GPIO_Init(ARD_D5_STMOD_TIM3_CH3_GPIO_Port, &GPIO_InitStruct);

  /*Configure GPIO pin : PMOD_RESET_Pin */
  GPIO_InitStruct.Pin = PMOD_RESET_Pin;
  GPIO_InitStruct.Mode = GPIO_MODE_INPUT;
  GPIO_InitStruct.Pull = GPIO_NOPULL;
  HAL_GPIO_Init(PMOD_RESET_GPIO_Port, &GPIO_InitStruct);

  /*Configure GPIO pins : PB14 PB15 */
  GPIO_InitStruct.Pin = GPIO_PIN_14|GPIO_PIN_15;
  GPIO_InitStruct.Mode = GPIO_MODE_AF_PP;
  GPIO_InitStruct.Pull = GPIO_NOPULL;
  GPIO_InitStruct.Speed = GPIO_SPEED_FREQ_VERY_HIGH;
  GPIO_InitStruct.Alternate = GPIO_AF12_OTG_HS_FS;
  HAL_GPIO_Init(GPIOB, &GPIO_InitStruct);

}

/* MPU Configuration */

void MPU_Config(void)
{
  MPU_Region_InitTypeDef MPU_InitStruct = {0};

  /* Disables the MPU */
  HAL_MPU_Disable();

  /** Initializes and configures the Region and the memory to be protected
  */
  MPU_InitStruct.Enable = MPU_REGION_ENABLE;
  MPU_InitStruct.Number = MPU_REGION_NUMBER0;
  MPU_InitStruct.BaseAddress = 0x64000000;
  MPU_InitStruct.Size = MPU_REGION_SIZE_1MB;
  MPU_InitStruct.SubRegionDisable = 0x0;
  MPU_InitStruct.TypeExtField = MPU_TEX_LEVEL0;
  MPU_InitStruct.AccessPermission = MPU_REGION_FULL_ACCESS;
  MPU_InitStruct.DisableExec = MPU_INSTRUCTION_ACCESS_ENABLE;
  MPU_InitStruct.IsShareable = MPU_ACCESS_SHAREABLE;
  MPU_InitStruct.IsCacheable = MPU_ACCESS_CACHEABLE;
  MPU_InitStruct.IsBufferable = MPU_ACCESS_BUFFERABLE;

  HAL_MPU_ConfigRegion(&MPU_InitStruct);
  /* Enables the MPU */
  HAL_MPU_Enable(MPU_PRIVILEGED_DEFAULT);

}

void Error_Handler(void)
{
  __disable_irq();
  while (1)
  {
  }
}
